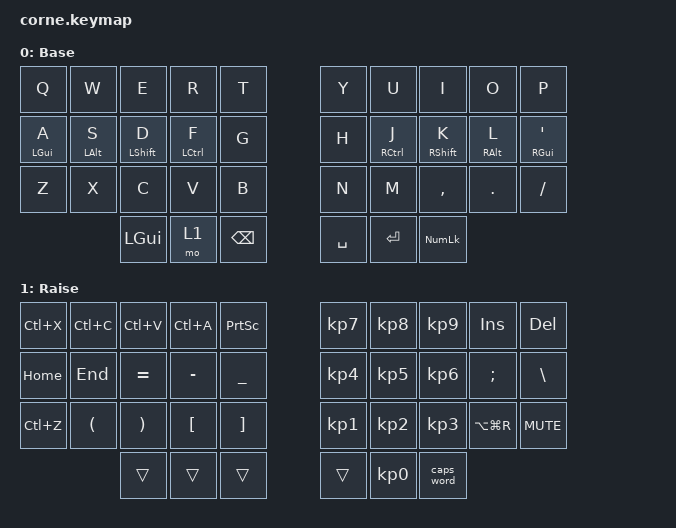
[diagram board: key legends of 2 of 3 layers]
/*
 * Copyright (c) 2020 The ZMK Contributors
 *
 * SPDX-License-Identifier: MIT
 */
/*     36 KEY MATRIX / LAYOUT MAPPING
  ╭────────────────────┬─────────────────────╮ 
  │  0   1   2   3   4 │ 5   6   7   8   9   │ 
  │ 10  11  12  13  14 │ 15  16  17  18  19  │ 
  │ 20  21  22  23  24 │ 25  26  27  28  29  │ 
  ╰──────╮ 30  31  32  │ 33  34  35 ╭────────╯ 
          ╰────────────┴───────────╯             */

#include <behaviors.dtsi>
#include <dt-bindings/zmk/bt.h>
#include <dt-bindings/zmk/keys.h>

#define DEFAULT 0 // use
#define RAISE 1 // use
#define LOWER 2 // no use
#define KEYS_L 0 1 2 3 4 10 11 12 13 14 20 21 22 23 24 // left-hand keys
#define KEYS_R 5 6 7 8 9 15 16 17 18 19 25 26 27 28 29 // right-hand keys
#define THUMBS 30 31 32 33 34 35
#define TAPPING_TERM 200
#define QUICK_TAP    100

#define COMBO(NAME, BINDINGS, KEYPOS, LAYERS) \
  combo_##NAME { \
    timeout-ms = <25>; \
    bindings = <BINDINGS>; \
    key-positions = <KEYPOS>; \
    layers = <LAYERS>; \
  };

&caps_word { continue-list = <UNDERSCORE MINUS SPACE SINGLE_QUOTE DOUBLE_QUOTES EXCLAMATION QUESTION BACKSPACE>; };

&lt {
    flavor = "tap-preferred";
    tapping-term-ms = <TAPPING_TERM>;
};

&mt {
    flavor = "tap-preferred";
    tapping-term-ms = <TAPPING_TERM>;
};

/ {
    behaviors {
        hm: homerow_mods {
            compatible = "zmk,behavior-hold-tap";
            label = "LAYER_MODS";
            #binding-cells = <2>;
            tapping-term-ms = <TAPPING_TERM>;
            quick_tap_ms = <0>;
            flavor = "tap-preferred";
            bindings = <&kp>, <&kp>;
        };

        hml: homerow_mods_left {
            compatible = "zmk,behavior-hold-tap";
            label = "HOMEROW_MODS_LEFT";
            #binding-cells = <2>;
            tapping-term-ms = <TAPPING_TERM>;
            quick_tap_ms = <0>;
            flavor = "tap-preferred";
            bindings = <&kp>, <&kp>;

            hold-trigger-key-positions = <KEYS_R THUMBS>;
            hold-trigger-on-release;             // delay positional check until key-release
        };

        hmr: homerow_mods_right {
            compatible = "zmk,behavior-hold-tap";
            label = "HOMEROW_MODS_RIGHT";
            #binding-cells = <2>;
            tapping-term-ms = <TAPPING_TERM>;
            quick_tap_ms = <0>;
            flavor = "tap-preferred";
            bindings = <&kp>, <&kp>;

            hold-trigger-key-positions = <KEYS_L THUMBS>;
            hold-trigger-on-release;             // delay positional check until key-release
        };

        hs: homerow_shift {
            compatible = "zmk,behavior-hold-tap";
            label = "HOMEROW_SHIFT";
            #binding-cells = <2>;
            tapping-term-ms = <TAPPING_TERM>;
            quick_tap_ms = <0>;
            flavor = "tap-preferred";
            bindings = <&kp>, <&kp>;
        };
    };

    /*     36 KEY MATRIX / LAYOUT MAPPING
  ╭────────────────────┬─────────────────────╮ 
  │  0   1   2   3   4 │ 5   6   7   8   9   │ 
  │ 10  11  12  13  14 │ 15  16  17  18  19  │ 
  │ 20  21  22  23  24 │ 25  26  27  28  29  │ 
  ╰──────╮ 30  31  32  │ 33  34  35 ╭────────╯ 
          ╰────────────┴───────────╯             */

    combos {
        compatible = "zmk,combos";

                COMBO(escape, &kp ESC, 0 1, DEFAULT RAISE LOWER) 
                COMBO(tab, &kp TAB, 1 2, DEFAULT RAISE LOWER) 
                COMBO(page_up, &kp PAGE_UP, 2 3, DEFAULT RAISE LOWER) 
                COMBO(page_down, &kp PAGE_DOWN, 3 4, DEFAULT RAISE LOWER) 
                COMBO(exclamation,&kp EXCL, 0 10, DEFAULT RAISE LOWER) 
                COMBO(alias,&kp AT, 1 11, DEFAULT RAISE LOWER)
                COMBO(hash,&kp HASH, 2 12, DEFAULT RAISE LOWER) 
                COMBO(dollar,&kp DOLLAR, 3 13,DEFAULT RAISE LOWER) 
                COMBO(percent,&kp PERCENT, 4 14, DEFAULT RAISE LOWER) 
                COMBO(caret,&kp CARET, 5 15, DEFAULT RAISE LOWER) 
                COMBO(ampersand,&kp AMPS, 6 16, DEFAULT RAISE LOWER) 
                COMBO(asterisk,&kp ASTRK,  7 17, DEFAULT RAISE LOWER) 
                COMBO(leftpar,&kp LPAR, 8 18, DEFAULT RAISE LOWER) 
                COMBO(rightpar,&kp RPAR, 9 19, DEFAULT RAISE LOWER)
                COMBO(f1,&kp F1, 10 20, DEFAULT RAISE LOWER) 
                COMBO(f2,&kp F2, 11 21, DEFAULT RAISE LOWER)
                COMBO(f3,&kp F3, 12 22, DEFAULT RAISE LOWER) 
                COMBO(f4,&kp F4, 13 23, DEFAULT RAISE LOWER) 
                COMBO(f5,&kp F5, 14 24, DEFAULT RAISE LOWER) 
                COMBO(f6,&kp F6, 15 25, DEFAULT RAISE LOWER) 
                COMBO(f7,&kp F7, 16 26, DEFAULT RAISE LOWER) 
                COMBO(f8,&kp F8, 17 27, DEFAULT RAISE LOWER) 
                COMBO(f9,&kp F9, 18 28, DEFAULT RAISE LOWER) 
                COMBO(f10,&kp F10, 19 29, DEFAULT RAISE LOWER)
                COMBO(btclr,&bt BT_CLR, 0 9, DEFAULT RAISE LOWER)
                COMBO(btsel1,&bt BT_SEL 0, 10 19, DEFAULT RAISE LOWER) 
                COMBO(btsel2,&bt BT_SEL 1, 20 29, DEFAULT RAISE LOWER) 
                COMBO(btnext,&bt BT_NXT, 5 6, DEFAULT RAISE LOWER) 
                COMBO(btprev,&bt BT_PRV, 6 7, DEFAULT RAISE LOWER) 
                COMBO(gaming,&tog 2, 24 25, DEFAULT RAISE LOWER)
    };

    chosen { zmk,matrix_transform = &five_column_transform; };

    keymap {
        compatible = "zmk,keymap";

        default_layer {
            // -----------------------------------------------------------------------------------------
            // |  Q  |  W  |  E  |  R  |  T  |     |  Y  |  U   |  I   |  O   | P |
            // |  A  |  S  |  D  |  F  |  G  |     |  H  |  J   |  K   |  L   | ' | 
            // |  Z  |  X  |  C  |  V  |  B  |     |  N  |  M   |  ,   |  .   | / |
            //             | GUI | RSE | BSPC |   | SPC | ENT  | NUM |

            display-name = "Base";
            bindings = <
  &kp Q          &kp W          &kp E     &kp R              &kp T       &kp Y      &kp U      &kp I         &kp O        &kp P
  &hml LGUI A  &hml LALT S  &hml LSHFT D  &hml LCTRL F       &kp G       &kp H    &hmr RCTRL J &hmr RSHFT K  &hmr RALT L  &hmr RGUI APOS
  &kp Z          &kp X          &kp C     &kp V              &kp B       &kp N      &kp M      &kp COMMA     &kp DOT      &kp FSLH
                                &kp LGUI  &mo 1  &kp BSPC    &kp SPACE   &kp ENTER  &kp KP_NUM
            >;
        };

raise_layer {
            // -----------------------------------------------------------------------------------------
            // | C(X) | C(C) | C(V) | C(A) | PSCN |     |   7  |  8  |  9   | INS  | DEL  |
            // | HOME | END  |  +=  |  -_  |  __  |     |   4  |  5  |  6   | SEMI |  \|  |
            // | C(Z) |  (   |  )   |  [{  |  }]  |     |   1  |  2  |  3   | REC  | MUTE |
            //               | NULL | NULL | NULL |     | NULL |  0  | CAPS |

            display-name = "Raise";
            bindings = <
  &kp LC(X)   &kp LC(C)     &kp LC(V)     &kp LC(A)    &kp PSCRN          &kp KP_N7  &kp KP_N8   &kp KP_N9     &kp INS      &kp DEL
  &kp HOME    &kp END       &kp EQUAL     &kp MINUS    &kp UNDER          &kp KP_N4  &kp KP_N5   &kp KP_N6     &kp SEMI     &kp BSLH 
  &kp LC(Z)   &kp LPAR      &kp RPAR      &kp LBKT     &kp RBKT           &kp KP_N1  &kp KP_N2   &kp KP_N3   &kp LA(LG(R))  &kp C_MUTE
                            &trans        &trans       &trans             &trans     &kp KP_N0   &caps_word
            >;
        };

        lower_layer {
            // -----------------------------------------------------------------------------------------
            // | !     |  @  |  #  |  $  |  %  |     |  ^  |  &  |  *  |  (  |  )  |
            // | BT1   | BT2 | BT3 | BT4 | BT5 |     | LFT | DWN |  UP | RGT |     |
            // | BTCLR |     |     |     |     |     |     |     |     |     |     |
            //               | GUI |     | SPC |     | ENT | ESC | TAB |

            display-name = "Lower";
            bindings = <
  &kp Q       &kp W         &kp E         &kp R       &kp T             &kp Y       &kp U        &kp I         &kp O        &kp P
  &kp A       &kp S         &kp D         &kp F       &kp G             &kp H    &hmr RCTRL J &hmr RSHFT K  &hmr RALT L  &hmr RGUI APOS
  &kp Z       &kp X         &kp C         &kp V       &kp B             &kp N       &kp M      &kp COMMA      &kp DOT      &kp FSLH      &none
                          &mt LALT LGUI   &mo 1    &kp BSPC             &kp SPACE   &kp ENTER  &kp KP_NUM
            >;
        };

    };
};
